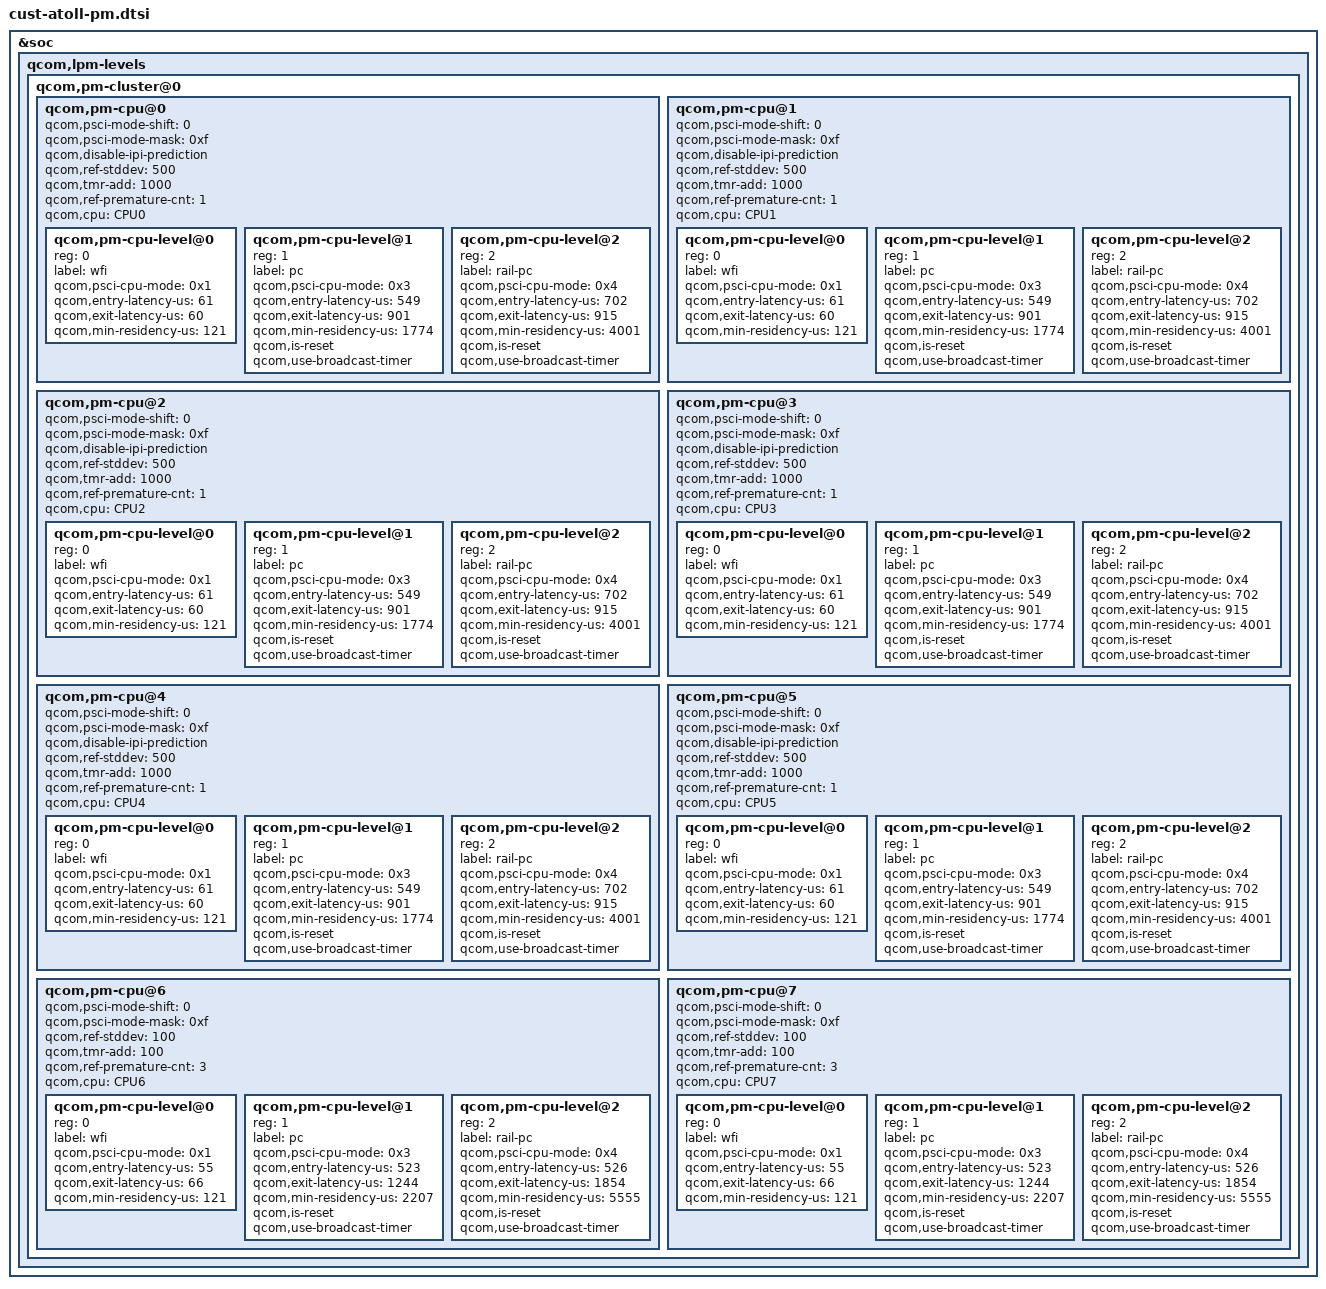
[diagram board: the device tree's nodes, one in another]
&soc {
        qcom,lpm-levels {
                qcom,pm-cluster@0 {

			qcom,pm-cpu@0 {
				#address-cells = <1>;
				#size-cells = <0>;
				qcom,psci-mode-shift = <0>;
				qcom,psci-mode-mask = <0xf>;
				qcom,disable-ipi-prediction;
				qcom,ref-stddev = <500>;
				qcom,tmr-add = <1000>;
				qcom,ref-premature-cnt = <1>;
				qcom,cpu = <&CPU0>;

				qcom,pm-cpu-level@0 { /* C1 */
					reg = <0>;
					label = "wfi";
					qcom,psci-cpu-mode = <0x1>;
					qcom,entry-latency-us = <61>;
					qcom,exit-latency-us = <60>;
					qcom,min-residency-us = <121>;
				};

				qcom,pm-cpu-level@1 {  /* C3 */
					reg = <1>;
					label = "pc";
					qcom,psci-cpu-mode = <0x3>;
					qcom,entry-latency-us = <549>;
					qcom,exit-latency-us = <901>;
					qcom,min-residency-us = <1774>;
					qcom,is-reset;
					qcom,use-broadcast-timer;
				};

				qcom,pm-cpu-level@2 {  /* C4 */
					reg = <2>;
					label = "rail-pc";
					qcom,psci-cpu-mode = <0x4>;
					qcom,entry-latency-us = <702>;
					qcom,exit-latency-us = <915>;
					qcom,min-residency-us = <4001>;
					qcom,is-reset;
					qcom,use-broadcast-timer;
				};
			};

			qcom,pm-cpu@1 {
				#address-cells = <1>;
				#size-cells = <0>;
				qcom,psci-mode-shift = <0>;
				qcom,psci-mode-mask = <0xf>;
				qcom,disable-ipi-prediction;
				qcom,ref-stddev = <500>;
				qcom,tmr-add = <1000>;
				qcom,ref-premature-cnt = <1>;
				qcom,cpu = <&CPU1>;
				
				qcom,pm-cpu-level@0 { /* C1 */
					reg = <0>;
					label = "wfi";
					qcom,psci-cpu-mode = <0x1>;
					qcom,entry-latency-us = <61>;
					qcom,exit-latency-us = <60>;
					qcom,min-residency-us = <121>;
				};

				qcom,pm-cpu-level@1 {  /* C3 */
					reg = <1>;
					label = "pc";
					qcom,psci-cpu-mode = <0x3>;
					qcom,entry-latency-us = <549>;
					qcom,exit-latency-us = <901>;
					qcom,min-residency-us = <1774>;
					qcom,is-reset;
					qcom,use-broadcast-timer;
				};

				qcom,pm-cpu-level@2 {  /* C4 */
					reg = <2>;
					label = "rail-pc";
					qcom,psci-cpu-mode = <0x4>;
					qcom,entry-latency-us = <702>;
					qcom,exit-latency-us = <915>;
					qcom,min-residency-us = <4001>;
					qcom,is-reset;
					qcom,use-broadcast-timer;
				};
			};

			qcom,pm-cpu@2 {
				#address-cells = <1>;
				#size-cells = <0>;
				qcom,psci-mode-shift = <0>;
				qcom,psci-mode-mask = <0xf>;
				qcom,disable-ipi-prediction;
				qcom,ref-stddev = <500>;
				qcom,tmr-add = <1000>;
				qcom,ref-premature-cnt = <1>;
				qcom,cpu = <&CPU2>;

				qcom,pm-cpu-level@0 { /* C1 */
					reg = <0>;
					label = "wfi";
					qcom,psci-cpu-mode = <0x1>;
					qcom,entry-latency-us = <61>;
					qcom,exit-latency-us = <60>;
					qcom,min-residency-us = <121>;
				};

				qcom,pm-cpu-level@1 {  /* C3 */
					reg = <1>;
					label = "pc";
					qcom,psci-cpu-mode = <0x3>;
					qcom,entry-latency-us = <549>;
					qcom,exit-latency-us = <901>;
					qcom,min-residency-us = <1774>;
					qcom,is-reset;
					qcom,use-broadcast-timer;
				};

				qcom,pm-cpu-level@2 {  /* C4 */
					reg = <2>;
					label = "rail-pc";
					qcom,psci-cpu-mode = <0x4>;
					qcom,entry-latency-us = <702>;
					qcom,exit-latency-us = <915>;
					qcom,min-residency-us = <4001>;
					qcom,is-reset;
					qcom,use-broadcast-timer;
				};
			};

			qcom,pm-cpu@3 {
				#address-cells = <1>;
				#size-cells = <0>;
				qcom,psci-mode-shift = <0>;
				qcom,psci-mode-mask = <0xf>;
				qcom,disable-ipi-prediction;
				qcom,ref-stddev = <500>;
				qcom,tmr-add = <1000>;
				qcom,ref-premature-cnt = <1>;
				qcom,cpu = <&CPU3>;

				qcom,pm-cpu-level@0 { /* C1 */
					reg = <0>;
					label = "wfi";
					qcom,psci-cpu-mode = <0x1>;
					qcom,entry-latency-us = <61>;
					qcom,exit-latency-us = <60>;
					qcom,min-residency-us = <121>;
				};

				qcom,pm-cpu-level@1 {  /* C3 */
					reg = <1>;
					label = "pc";
					qcom,psci-cpu-mode = <0x3>;
					qcom,entry-latency-us = <549>;
					qcom,exit-latency-us = <901>;
					qcom,min-residency-us = <1774>;
					qcom,is-reset;
					qcom,use-broadcast-timer;
				};

				qcom,pm-cpu-level@2 {  /* C4 */
					reg = <2>;
					label = "rail-pc";
					qcom,psci-cpu-mode = <0x4>;
					qcom,entry-latency-us = <702>;
					qcom,exit-latency-us = <915>;
					qcom,min-residency-us = <4001>;
					qcom,is-reset;
					qcom,use-broadcast-timer;
				};
			};

			qcom,pm-cpu@4 {
				#address-cells = <1>;
				#size-cells = <0>;
				qcom,psci-mode-shift = <0>;
				qcom,psci-mode-mask = <0xf>;
				qcom,disable-ipi-prediction;
				qcom,ref-stddev = <500>;
				qcom,tmr-add = <1000>;
				qcom,ref-premature-cnt = <1>;
				qcom,cpu = <&CPU4>;

				qcom,pm-cpu-level@0 { /* C1 */
					reg = <0>;
					label = "wfi";
					qcom,psci-cpu-mode = <0x1>;
					qcom,entry-latency-us = <61>;
					qcom,exit-latency-us = <60>;
					qcom,min-residency-us = <121>;
				};

				qcom,pm-cpu-level@1 {  /* C3 */
					reg = <1>;
					label = "pc";
					qcom,psci-cpu-mode = <0x3>;
					qcom,entry-latency-us = <549>;
					qcom,exit-latency-us = <901>;
					qcom,min-residency-us = <1774>;
					qcom,is-reset;
					qcom,use-broadcast-timer;
				};

				qcom,pm-cpu-level@2 {  /* C4 */
					reg = <2>;
					label = "rail-pc";
					qcom,psci-cpu-mode = <0x4>;
					qcom,entry-latency-us = <702>;
					qcom,exit-latency-us = <915>;
					qcom,min-residency-us = <4001>;
					qcom,is-reset;
					qcom,use-broadcast-timer;
				};
			};

			qcom,pm-cpu@5 {
				#address-cells = <1>;
				#size-cells = <0>;
				qcom,psci-mode-shift = <0>;
				qcom,psci-mode-mask = <0xf>;
				qcom,disable-ipi-prediction;
				qcom,ref-stddev = <500>;
				qcom,tmr-add = <1000>;
				qcom,ref-premature-cnt = <1>;
				qcom,cpu = <&CPU5>;

				qcom,pm-cpu-level@0 { /* C1 */
					reg = <0>;
					label = "wfi";
					qcom,psci-cpu-mode = <0x1>;
					qcom,entry-latency-us = <61>;
					qcom,exit-latency-us = <60>;
					qcom,min-residency-us = <121>;
				};

				qcom,pm-cpu-level@1 {  /* C3 */
					reg = <1>;
					label = "pc";
					qcom,psci-cpu-mode = <0x3>;
					qcom,entry-latency-us = <549>;
					qcom,exit-latency-us = <901>;
					qcom,min-residency-us = <1774>;
					qcom,is-reset;
					qcom,use-broadcast-timer;
				};

				qcom,pm-cpu-level@2 {  /* C4 */
					reg = <2>;
					label = "rail-pc";
					qcom,psci-cpu-mode = <0x4>;
					qcom,entry-latency-us = <702>;
					qcom,exit-latency-us = <915>;
					qcom,min-residency-us = <4001>;
					qcom,is-reset;
					qcom,use-broadcast-timer;
				};
			};
			
			qcom,pm-cpu@6 {
				#address-cells = <1>;
				#size-cells = <0>;
				qcom,psci-mode-shift = <0>;
				qcom,psci-mode-mask = <0xf>;
				qcom,ref-stddev = <100>;
				qcom,tmr-add = <100>;
				qcom,ref-premature-cnt = <3>;
				qcom,cpu = <&CPU6>;

				qcom,pm-cpu-level@0 { /* C1 */
					reg = <0>;
					label = "wfi";
					qcom,psci-cpu-mode = <0x1>;
					qcom,entry-latency-us = <55>;
					qcom,exit-latency-us = <66>;
					qcom,min-residency-us = <121>;
				};

				qcom,pm-cpu-level@1 {  /* C3 */
					reg = <1>;
					label = "pc";
					qcom,psci-cpu-mode = <0x3>;
					qcom,entry-latency-us = <523>;
					qcom,exit-latency-us = <1244>;
					qcom,min-residency-us = <2207>;
					qcom,is-reset;
					qcom,use-broadcast-timer;
				};

				qcom,pm-cpu-level@2 {  /* C4 */
					reg = <2>;
					label = "rail-pc";
					qcom,psci-cpu-mode = <0x4>;
					qcom,entry-latency-us = <526>;
					qcom,exit-latency-us = <1854>;
					qcom,min-residency-us = <5555>;
					qcom,is-reset;
					qcom,use-broadcast-timer;
				};
			};

			qcom,pm-cpu@7 {
				#address-cells = <1>;
				#size-cells = <0>;
				qcom,psci-mode-shift = <0>;
				qcom,psci-mode-mask = <0xf>;
				qcom,ref-stddev = <100>;
				qcom,tmr-add = <100>;
				qcom,ref-premature-cnt = <3>;
				qcom,cpu = <&CPU7>;

				qcom,pm-cpu-level@0 { /* C1 */
					reg = <0>;
					label = "wfi";
					qcom,psci-cpu-mode = <0x1>;
					qcom,entry-latency-us = <55>;
					qcom,exit-latency-us = <66>;
					qcom,min-residency-us = <121>;
				};

				qcom,pm-cpu-level@1 {  /* C3 */
					reg = <1>;
					label = "pc";
					qcom,psci-cpu-mode = <0x3>;
					qcom,entry-latency-us = <523>;
					qcom,exit-latency-us = <1244>;
					qcom,min-residency-us = <2207>;
					qcom,is-reset;
					qcom,use-broadcast-timer;
				};

				qcom,pm-cpu-level@2 {  /* C4 */
					reg = <2>;
					label = "rail-pc";
					qcom,psci-cpu-mode = <0x4>;
					qcom,entry-latency-us = <526>;
					qcom,exit-latency-us = <1854>;
					qcom,min-residency-us = <5555>;
					qcom,is-reset;
					qcom,use-broadcast-timer;
				};
			};
		};
	};
};
